# ATSAM3S4C device description
Architecture: CORTEX-M3; Family: SAM3; Series: SAM3S
Registers are 32-bit, read-write, no defined reset value unless marked. A register's access mark holds for its fields unless they carry their own. Offsets are from the block's base; [hi:lo] are bit positions; {n}, {i} and the like mark numbered series.

## RTT — Real-time Timer
Instances: RTT 0x400E1430
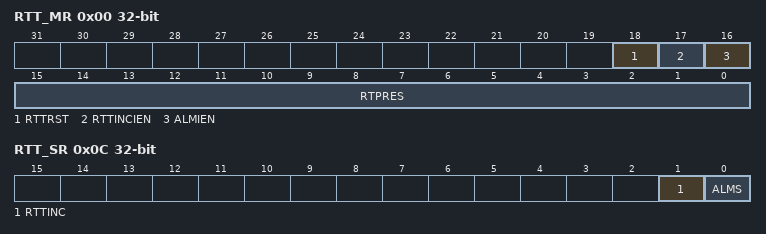
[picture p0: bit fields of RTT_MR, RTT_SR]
0x00 RTT_MR — Mode Register
  [18] RTTRST — Real-time Timer Restart
  [17] RTTINCIEN — Real-time Timer Increment Interrupt Enable
  [16] ALMIEN — Alarm Interrupt Enable
  [15:0] RTPRES — Real-time Timer Prescaler Value
0x04 RTT_AR — Alarm Register
  [31:0] ALMV — Alarm Value
0x08 RTT_VR ro — Value Register
  [31:0] CRTV — Current Real-time Value
0x0C RTT_SR ro — Status Register
  [1] RTTINC — Real-time Timer Increment
  [0] ALMS — Real-time Alarm Status

## SMC — Static Memory Controller
Instances: SMC 0x400E0000
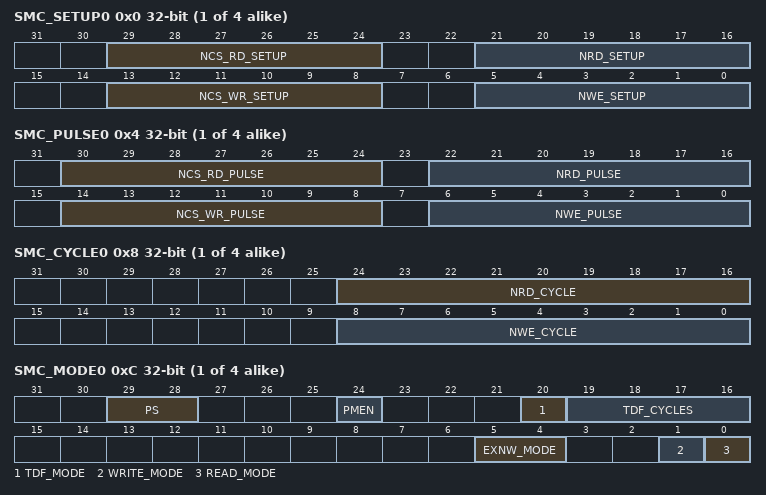
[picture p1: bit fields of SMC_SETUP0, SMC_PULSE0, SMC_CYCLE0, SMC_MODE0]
{0x0+0x10*i} SMC_SETUP{i} (i=0..3) — SMC Setup Register (CS_number = {i})
  [29:24] NCS_RD_SETUP — NCS Setup Length in READ Access
  [21:16] NRD_SETUP — NRD Setup Length
  [13:8] NCS_WR_SETUP — NCS Setup Length in WRITE Access
  [5:0] NWE_SETUP — NWE Setup Length
{0x4+0x10*i} SMC_PULSE{i} (i=0..3) — SMC Pulse Register (CS_number = {i})
  [30:24] NCS_RD_PULSE — NCS Pulse Length in READ Access
  [22:16] NRD_PULSE — NRD Pulse Length
  [14:8] NCS_WR_PULSE — NCS Pulse Length in WRITE Access
  [6:0] NWE_PULSE — NWE Pulse Length
{0x8+0x10*i} SMC_CYCLE{i} (i=0..3) — SMC Cycle Register (CS_number = {i})
  [24:16] NRD_CYCLE — Total Read Cycle Length
  [8:0] NWE_CYCLE — Total Write Cycle Length
{0xC+0x10*i} SMC_MODE{i} (i=0..3) — SMC Mode Register (CS_number = {i})
  [29:28] PS — Page Size
    0=_4_BYTE (4-byte page); 1=_8_BYTE (8-byte page); 2=_16_BYTE (16-byte page); 3=_32_BYTE (32-byte page)
  [24] PMEN — Page Mode Enabled
  [20] TDF_MODE — TDF Optimization
  [19:16] TDF_CYCLES — Data Float Time
  [5:4] EXNW_MODE — NWAIT Mode
    0=DISABLED; 2=FROZEN (Frozen Mode); 3=READY (Ready Mode)
  [1] WRITE_MODE
  [0] READ_MODE
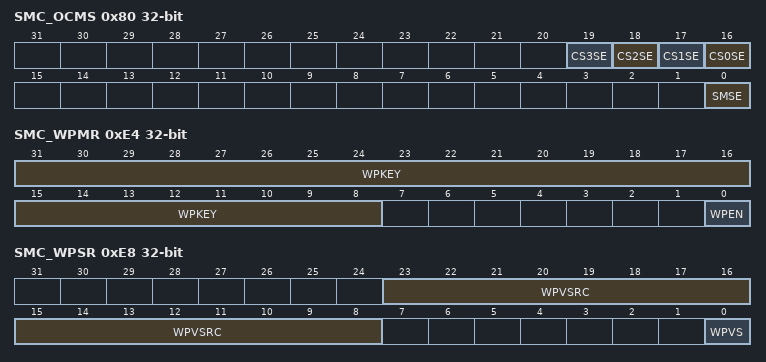
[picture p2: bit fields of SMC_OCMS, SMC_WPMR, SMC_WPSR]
0x80 SMC_OCMS — SMC OCMS MODE Register
  [n+16] CS{n}SE (n=0..3) — Chip Select (x = 0 to 3) Scrambling Enable
  [0] SMSE — Static Memory Controller Scrambling Enable
0x84 SMC_KEY1 wo — SMC OCMS KEY1 Register
  [31:0] KEY1 — Off Chip Memory Scrambling (OCMS) Key Part 1
0x88 SMC_KEY2 wo — SMC OCMS KEY2 Register
  [31:0] KEY2 — Off Chip Memory Scrambling (OCMS) Key Part 2
0xE4 SMC_WPMR — SMC Write Protect Mode Register
  [31:8] WPKEY — Write Protect KEY
  [0] WPEN — Write Protect Enable
0xE8 SMC_WPSR ro — SMC Write Protect Status Register
  [23:8] WPVSRC — Write Protect Violation Source
  [0] WPVS — Write Protect Enable

## UDP — USB Device Port
Instances: UDP 0x40034000
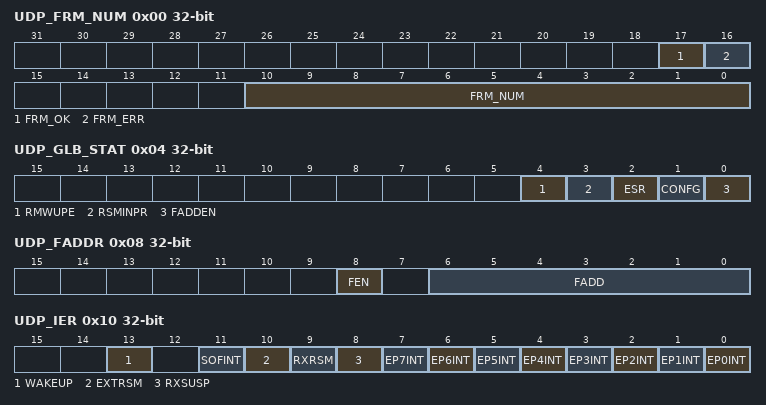
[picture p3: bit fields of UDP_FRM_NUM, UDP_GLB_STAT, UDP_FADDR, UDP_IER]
0x00 UDP_FRM_NUM ro — Frame Number Register
  [17] FRM_OK — Frame OK
  [16] FRM_ERR — Frame Error
  [10:0] FRM_NUM — Frame Number as Defined in the Packet Field Formats
0x04 UDP_GLB_STAT — Global State Register
  [4] RMWUPE — Remote Wake Up Enable
  [3] RSMINPR
  [2] ESR — Enable Send Resume
  [1] CONFG — Configured
  [0] FADDEN — Function Address Enable
0x08 UDP_FADDR — Function Address Register
  [8] FEN — Function Enable
  [6:0] FADD — Function Address Value
0x10 UDP_IER wo — Interrupt Enable Register
  [13] WAKEUP — Enable UDP bus Wakeup Interrupt
  [11] SOFINT — Enable Start Of Frame Interrupt
  [10] EXTRSM
  [9] RXRSM — Enable UDP Resume Interrupt
  [8] RXSUSP — Enable UDP Suspend Interrupt
  [n] EP{n}INT (n=3..7) — Enable Endpoint {n} Interrupt
  [2] EP2INT — Enable Endpoint 2Interrupt
  [1] EP1INT — Enable Endpoint 1 Interrupt
  [0] EP0INT — Enable Endpoint 0 Interrupt
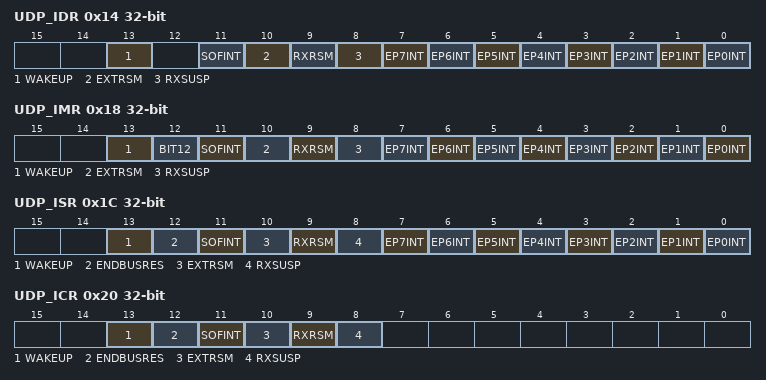
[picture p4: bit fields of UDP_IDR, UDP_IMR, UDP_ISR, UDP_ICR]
0x14 UDP_IDR wo — Interrupt Disable Register
  [13] WAKEUP — Disable USB Bus Interrupt
  [11] SOFINT — Disable Start Of Frame Interrupt
  [10] EXTRSM
  [9] RXRSM — Disable UDP Resume Interrupt
  [8] RXSUSP — Disable UDP Suspend Interrupt
  [n] EP{n}INT (n=0..7) — Disable Endpoint {n} Interrupt
0x18 UDP_IMR ro — Interrupt Mask Register
  [13] WAKEUP — USB Bus WAKEUP Interrupt
  [12] BIT12 — UDP_IMR Bit 12
  [11] SOFINT — Mask Start Of Frame Interrupt
  [10] EXTRSM
  [9] RXRSM — Mask UDP Resume Interrupt.
  [8] RXSUSP — Mask UDP Suspend Interrupt
  [n] EP{n}INT (n=0..7) — Mask Endpoint {n} Interrupt
0x1C UDP_ISR ro — Interrupt Status Register
  [13] WAKEUP — UDP Resume Interrupt Status
  [12] ENDBUSRES — End of BUS Reset Interrupt Status
  [11] SOFINT — Start of Frame Interrupt Status
  [10] EXTRSM
  [9] RXRSM — UDP Resume Interrupt Status
  [8] RXSUSP — UDP Suspend Interrupt Status
  [7] EP7INT — Endpoint 7Interrupt Status
  [n] EP{n}INT (n=0..6) — Endpoint {n} Interrupt Status
0x20 UDP_ICR wo — Interrupt Clear Register
  [13] WAKEUP — Clear Wakeup Interrupt
  [12] ENDBUSRES — Clear End of Bus Reset Interrupt
  [11] SOFINT — Clear Start Of Frame Interrupt
  [10] EXTRSM
  [9] RXRSM — Clear UDP Resume Interrupt
  [8] RXSUSP — Clear UDP Suspend Interrupt
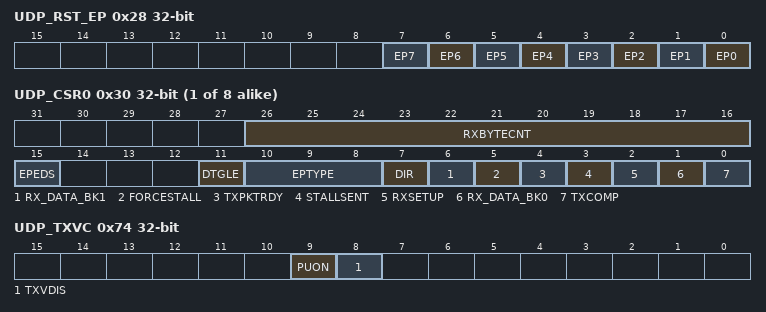
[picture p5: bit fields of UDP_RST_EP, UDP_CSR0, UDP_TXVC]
0x28 UDP_RST_EP — Reset Endpoint Register
  [n] EP{n} (n=0..7) — Reset Endpoint {n}
{0x30+4i} UDP_CSR{i} (i=0..7) — Endpoint Control and Status Register {i}
  [26:16] RXBYTECNT — Number of Bytes Available in the FIFO
  [15] EPEDS — Endpoint Enable Disable
  [11] DTGLE — Data Toggle
  [10:8] EPTYPE — Endpoint Type
    0=CTRL (Control); 1=ISO_OUT (Isochronous OUT); 2=BULK_OUT; 3=INT_OUT (Interrupt OUT); 5=ISO_IN (Isochronous IN); 6=BULK_IN; 7=INT_IN (Interrupt IN)
  [7] DIR — Transfer Direction (only available for control endpoints)
  [6] RX_DATA_BK1 — Receive Data Bank 1 (only used by endpoints with ping-pong attributes)
  [5] FORCESTALL — Force Stall (used by Control, Bulk and Isochronous Endpoints)
  [4] TXPKTRDY — Transmit Packet Ready
  [3] STALLSENT
  [2] RXSETUP — Received Setup
  [1] RX_DATA_BK0 — Receive Data Bank 0
  [0] TXCOMP — Generates an IN Packet with Data Previously Written in the DPR
{0x50+4i} UDP_FDR{i} (i=0..7) — Endpoint FIFO Data Register {i}
  [7:0] FIFO_DATA — FIFO Data Value
0x74 UDP_TXVC — Transceiver Control Register
  [9] PUON — Pull-up On
  [8] TXVDIS — Transceiver Disable

## WDT — Watchdog Timer
Instances: WDT 0x400E1450
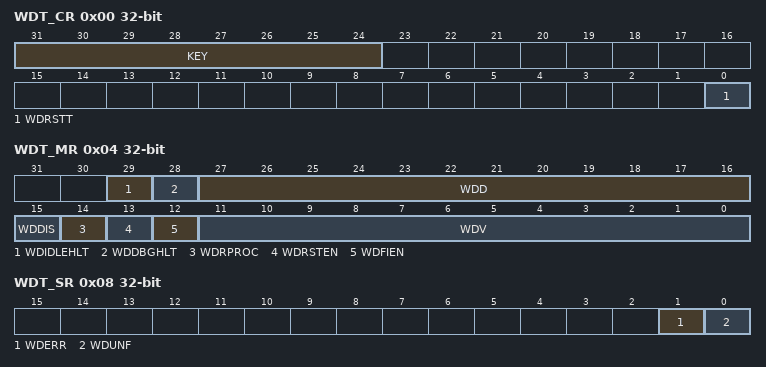
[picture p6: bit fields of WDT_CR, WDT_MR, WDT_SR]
0x00 WDT_CR wo — Control Register
  [31:24] KEY — Password.
    165=PASSWD (Writing any other value in this field aborts the write operation.)
  [0] WDRSTT — Watchdog Restart
0x04 WDT_MR — Mode Register
  [29] WDIDLEHLT — Watchdog Idle Halt
  [28] WDDBGHLT — Watchdog Debug Halt
  [27:16] WDD — Watchdog Delta Value
  [15] WDDIS — Watchdog Disable
  [14] WDRPROC — Watchdog Reset Processor
  [13] WDRSTEN — Watchdog Reset Enable
  [12] WDFIEN — Watchdog Fault Interrupt Enable
  [11:0] WDV — Watchdog Counter Value
0x08 WDT_SR ro — Status Register
  [1] WDERR — Watchdog Error
  [0] WDUNF — Watchdog Underflow

## GPNVMBITS (FUSES module)
Instances: GPNVMBITS 0 in fuses
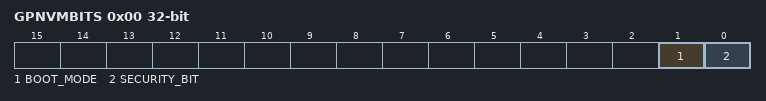
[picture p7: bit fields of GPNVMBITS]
0x00 GPNVMBITS
  [1] BOOT_MODE — Boot Mode Selection
  [0] SECURITY_BIT ro

## LOCKBIT
Instances: LOCKBIT 0 in lockbits
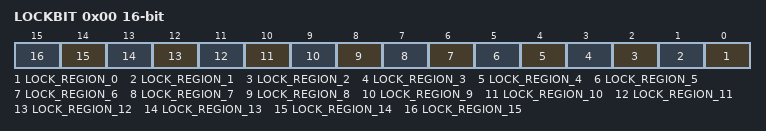
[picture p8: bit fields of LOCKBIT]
0x00 LOCKBIT 16-bit — Lock Bits
  [n] LOCK_REGION_{n} (n=0..15)

## SysTick — System timer
Instances: SysTick 0xE000E010
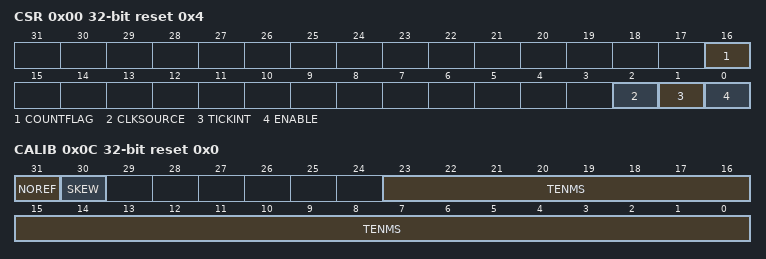
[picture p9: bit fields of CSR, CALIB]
0x00 CSR access not given reset 0x4 — SysTick Control and Status Register
  [16] COUNTFLAG
  [2] CLKSOURCE
    0=external clock; 1=processor clock
  [1] TICKINT
    0=counting down to 0 does not assert the SysTick exception request; 1=counting down to 0 asserts the SysTick exception request
  [0] ENABLE
    0=counter disabled; 1=counter enabled
0x04 RVR access not given reset 0x0 — SysTick Reload Value Register
  [23:0] RELOAD — Value to load into the SysTick Current Value Register when the counter reaches 0
0x08 CVR access not given reset 0x0 — SysTick Current Value Register
  [23:0] CURRENT — Current value at the time the register is accessed
0x0C CALIB access not given reset 0x0 — SysTick Calibration Value Register
  [31] NOREF
    0=The reference clock is provided; 1=The reference clock is not provided
  [30] SKEW
    0=10ms calibration value is exact; 1=10ms calibration value is inexact, because of the clock frequency
  [23:0] TENMS — Reload value to use for 10ms timing

## NVIC — Nested Vectored Interrupt Controller
Instances: NVIC 0xE000E100
{0x0+4i} NVICISER{i} access not given reset 0x0 (i=0..3) — Interrupt Set Enable Register n
  [31:0] SETENA — Interrupt set enable bits
{0x80+4i} NVICICER{i} access not given reset 0x0 (i=0..3) — Interrupt Clear Enable Register n
  [31:0] CLRENA — Interrupt clear-enable bits
{0x100+4i} NVICISPR{i} access not given reset 0x0 (i=0..3) — Interrupt Set Pending Register n
  [31:0] SETPEND — Interrupt set-pending bits
{0x180+4i} NVICICPR{i} access not given reset 0x0 (i=0..3) — Interrupt Clear Pending Register n
  [31:0] CLRPEND — Interrupt clear-pending bits
{0x200+4i} NVICIABR{i} access not given reset 0x0 (i=0..3) — Interrupt Active bit Register n
  [31:0] ACTIVE — Interrupt active flags
{0x300+i} NVICIP{i} 8-bit access not given reset 0x0 (i=0..105) — Interrupt Priority Register n
  [7:0] PRI{i} — Priority of interrupt {i}
0xE00 NVICSTIR access not given reset 0x0 — Software Trigger Interrupt Register
  [8:0] INTID — Interrupt ID of the interrupt to trigger, in the range 0-239. For example, a value of 0x03 specifies interrupt IRQ3.
